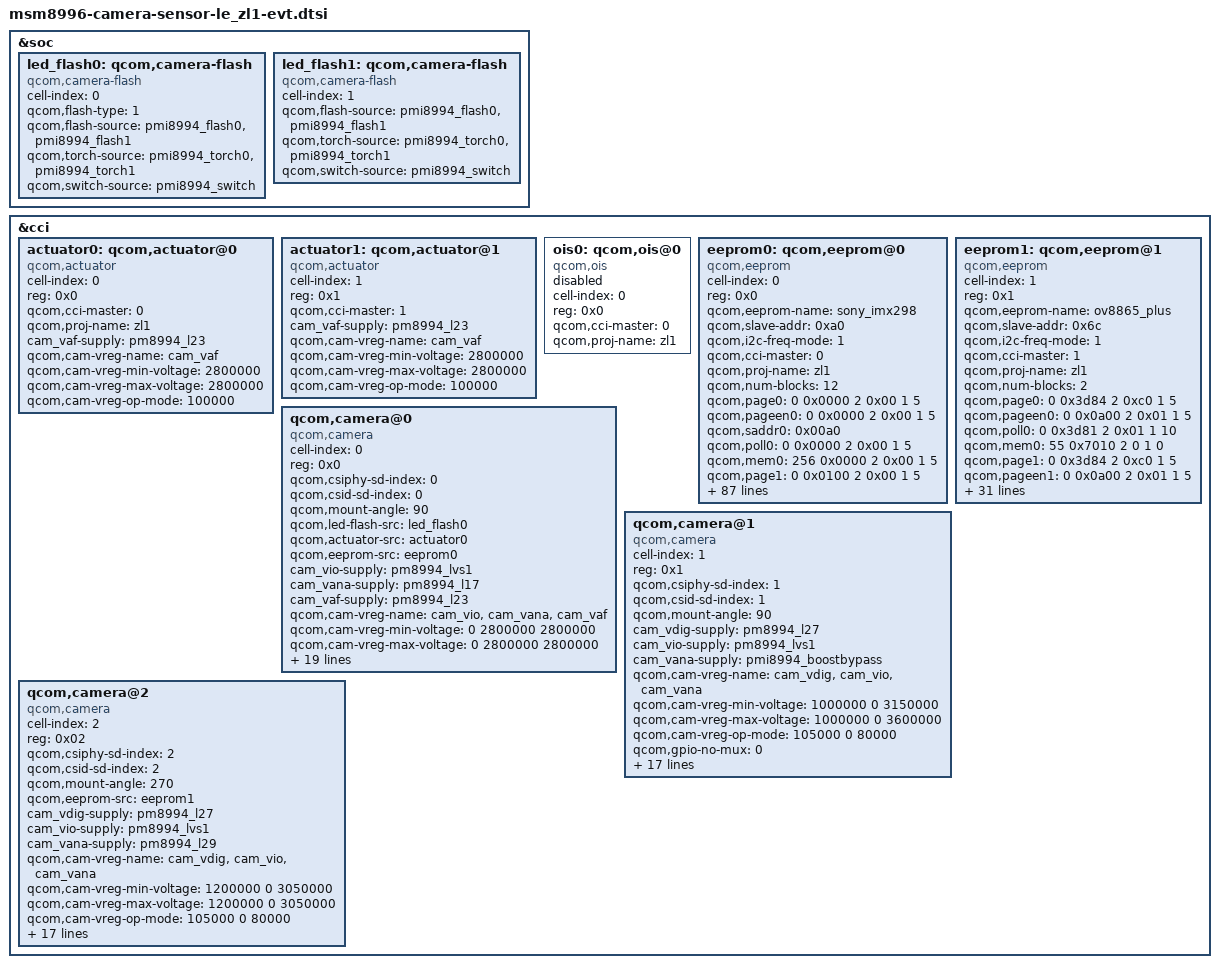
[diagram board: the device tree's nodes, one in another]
/*
 * Copyright (c) 2015 The Linux Foundation. All rights reserved.
 *
 * This program is free software; you can redistribute it and/or modify
 * it under the terms of the GNU General Public License version 2 and
 * only version 2 as published by the Free Software Foundation.
 *
 * This program is distributed in the hope that it will be useful,
 * but WITHOUT ANY WARRANTY; without even the implied warranty of
 * MERCHANTABILITY or FITNESS FOR A PARTICULAR PURPOSE.  See the
 * GNU General Public License for more details.
 */

&soc {
	led_flash0: qcom,camera-flash {
		cell-index = <0>;
		compatible = "qcom,camera-flash";
		qcom,flash-type = <1>;
		qcom,flash-source = <&pmi8994_flash0 &pmi8994_flash1>;
		qcom,torch-source = <&pmi8994_torch0 &pmi8994_torch1>;
		qcom,switch-source = <&pmi8994_switch>;
	};

	led_flash1: qcom,camera-flash {
		cell-index = <1>;
		compatible = "qcom,camera-flash";
		qcom,flash-source = <&pmi8994_flash0 &pmi8994_flash1>;
		qcom,torch-source = <&pmi8994_torch0 &pmi8994_torch1>;
		qcom,switch-source = <&pmi8994_switch>;
	};
};

&cci {
	actuator0: qcom,actuator@0 {
		cell-index = <0>;
		reg = <0x0>;
		compatible = "qcom,actuator";
		qcom,cci-master = <0>;
		qcom,proj-name = "zl1";
		cam_vaf-supply = <&pm8994_l23>;
		qcom,cam-vreg-name = "cam_vaf";
		qcom,cam-vreg-min-voltage = <2800000>;
		qcom,cam-vreg-max-voltage = <2800000>;
		qcom,cam-vreg-op-mode = <100000>;
	};

	actuator1: qcom,actuator@1 {
		cell-index = <1>;
		reg = <0x1>;
		compatible = "qcom,actuator";
		qcom,cci-master = <1>;
		cam_vaf-supply = <&pm8994_l23>;
		qcom,cam-vreg-name = "cam_vaf";
		qcom,cam-vreg-min-voltage = <2800000>;
		qcom,cam-vreg-max-voltage = <2800000>;
		qcom,cam-vreg-op-mode = <100000>;
	};

	ois0: qcom,ois@0 {
		cell-index = <0>;
		reg = <0x0>;
		compatible = "qcom,ois";
		qcom,cci-master = <0>;
		qcom,proj-name = "zl1";
		status = "disabled";
		/*
		cam_vaf-supply = <&pm8994_l23>;
		qcom,cam-vreg-name = "cam_vaf";
		qcom,cam-vreg-min-voltage = <2800000>;
		qcom,cam-vreg-max-voltage = <2800000>;
		qcom,cam-vreg-op-mode = <100000>;
		*/
	};

	eeprom0: qcom,eeprom@0 {
		cell-index = <0>;
		reg = <0x0>;
		qcom,eeprom-name = "sony_imx298";
		compatible = "qcom,eeprom";
		qcom,slave-addr = <0xa0>;
		qcom,i2c-freq-mode = <1>;
		qcom,cci-master = <0>;
		qcom,proj-name = "zl1";
		qcom,num-blocks = <12>;
		qcom,page0 = <0 0x0000 2 0x00 1 5>;
		qcom,pageen0 = <0 0x0000 2 0x00 1 5>;
		qcom,saddr0 = <0x00a0>;
		qcom,poll0 = <0 0x0000 2 0x00 1 5>;
		qcom,mem0 = <256 0x0000 2  0x00 1 5>;

		qcom,page1 = <0 0x0100 2 0x00 1 5>;
		qcom,pageen1 = <0 0x0100 2 0x00 1 5>;
		qcom,saddr1 = <0x00a0>;
		qcom,poll1 = <0 0x0100 2 0x00 1 5>;
		qcom,mem1 = <256 0x0100 2 0x00 1 0>;

		qcom,page2 = <0 0x0200 2 0x00 1 5>;
		qcom,pageen2 = <0 0x0200 2 0x00 1 5>;
		qcom,saddr2 = <0x00a0>;
		qcom,poll2 = <0 0x0200 2 0x00 1 5>;
		qcom,mem2 = <256 0x0200 2 0x00 1 0>;

		qcom,page3 = <0 0x0300 2 0x00 1 5>;
		qcom,pageen3 = <0 0x0300 2 0x00 1 5>;
		qcom,saddr3 = <0x00a0>;
		qcom,poll3 = <0 0x0300 2 0x00 1 5>;
		qcom,mem3 = <256 0x0300 2  0x00 1 5 >;

		qcom,page4 = <0 0x0400 2 0x00 1 5>;
		qcom,pageen4 = <0 0x0400 2 0x00 1 5>;
		qcom,saddr4 = <0x00a0>;
		qcom,poll4 = <0 0x0400 2 0x00 1 5>;
		qcom,mem4 = <256 0x0400 2 0x00 1 5>;

		qcom,page5 = <0 0x0500 2 0x00 1 5>;
		qcom,pageen5 = <0 0x0500 2 0x00 1 5>;
		qcom,saddr5 = <0x00a0>;
		qcom,poll5 = <0 0x0500 2 0x00 1 5>;
		qcom,mem5 = <256 0x0500 2  0x00 1 5>;

		qcom,page6 = <0 0x0600 2 0x00 1 5>;
		qcom,pageen6 = <0 0x0600 2 0x00 1 5>;
		qcom,saddr6 = <0x00a0>;
		qcom,poll6 = <0 0x0600 2 0x00 1 5>;
		qcom,mem6 = <256 0x0600 2 0x00 1 5>;

		qcom,page7 = <0 0x0700 2 0x00 1 5>;
		qcom,pageen7 = <0 0x0700 2 0x00 1 5>;
		qcom,saddr7 = <0x00a0>;
		qcom,poll7 = <0 0x0700 2 0x00 1 5>;
		qcom,mem7 = <256 0x0700 2 0x00 1 5>;

		qcom,page8 = <0 0x0800 2 0x00 1 5>;
		qcom,pageen8 = <0 0x0800 2 0x00 1 5>;
		qcom,saddr8 = <0x00a0>;
		qcom,poll8 = <0 0x0800 2 0x00 1 5>;
		qcom,mem8 = <256 0x0800 2  0x00 1 5>;

		qcom,page9 = <0 0x0900 2 0x00 1 5>;
		qcom,pageen9 = <0 0x0900 2 0x00 1 5>;
		qcom,saddr9 = <0x00a0>;
		qcom,poll9 = <0 0x0900 2 0x00 1 5>;
		qcom,mem9 = <256 0x0900 2  0x00 1 5>;

		qcom,page10 = <0 0x0A00 2 0x00 1 5>;
		qcom,pageen10 = <0 0x0A00 2 0x00 1 5>;
		qcom,saddr10 = <0x00a0>;
		qcom,poll10 = <0 0x0A00 2 0x00 1 5>;
		qcom,mem10 = <256 0x0A00 2  0x00 1 5>;

		qcom,page11 = <0 0x0B00 2 0x00 1 5>;
		qcom,pageen11 = <0 0x0B00 2 0x00 1 5>;
		qcom,saddr11 = <0x00a0>;
		qcom,poll11 = <0 0x0B00 2 0x00 1 5>;
		qcom,mem11 = <160 0x0B00 2  0x00 1 5>;

		cam_vio-supply = <&pm8994_lvs1>;
		cam_vana-supply = <&pm8994_l17>;
		cam_vaf-supply = <&pm8994_l23>;
		qcom,cam-vreg-name = "cam_vdig", "cam_vio", "cam_vana","cam_vaf";
		qcom,cam-vreg-min-voltage = <1100000 0 2500000 2800000>;
		qcom,cam-vreg-max-voltage = <1100000 0 2500000 2800000>;
		qcom,cam-vreg-op-mode = <105000 0 80000 100000>;
		qcom,gpio-no-mux = <0>;
		pinctrl-names = "cam_default", "cam_suspend";
		pinctrl-0 = <&cam_sensor_mclk0_active &cam_sensor_rear_active>;
		pinctrl-1 = <&cam_sensor_mclk0_suspend &cam_sensor_rear_suspend>;
		gpios = <&tlmm 13 0>,
			<&tlmm 29 0>,
			<&tlmm 38 0>;
		qcom,gpio-reset = <1>;
		qcom,gpio-vdig = <2>;
		qcom,gpio-req-tbl-num = <0 1 2>;
		qcom,gpio-req-tbl-flags = <1 0 0>;
		qcom,gpio-req-tbl-label = "CAMIF_MCLK0",
					  "CAM_RESET0",
					  "CAM_VDIG";
		qcom,cam-power-seq-type = "sensor_gpio", "sensor_vreg", "sensor_gpio",
			"sensor_vreg", "sensor_vreg" , "sensor_clk","sensor_gpio";
		qcom,cam-power-seq-val = "sensor_gpio_reset", "cam_vana", "sensor_gpio_vdig",
			"cam_vio", "cam_vaf","sensor_cam_mclk","sensor_gpio_reset";
		qcom,cam-power-seq-cfg-val = <1 1 1 1 1 24000000 0>;
		qcom,cam-power-seq-delay = <1 1 1 30 30 5 1>;
		status = "ok";
		clocks = <&clock_mmss clk_mclk0_clk_src>,
				<&clock_mmss clk_camss_mclk0_clk>;
		clock-names = "cam_src_clk", "cam_clk";
	};

	eeprom1: qcom,eeprom@1 {
		cell-index = <1>;
		reg = <0x1>;
		qcom,eeprom-name = "ov8865_plus";
		compatible = "qcom,eeprom";
		qcom,slave-addr = <0x6c>;
		qcom,i2c-freq-mode = <1>;
		qcom,cci-master = <1>;
		qcom,proj-name = "zl1";
		qcom,num-blocks = <2>;

		qcom,page0 = <0 0x3d84 2 0xc0 1 5>;
		qcom,pageen0 = <0 0x0a00 2 0x01 1 5>;
		qcom,poll0 = <0 0x3d81 2 0x01 1 10>;
		qcom,mem0 = <55 0x7010 2 0 1 0>;

		qcom,page1 = <0 0x3d84 2 0xc0 1 5>;
		qcom,pageen1 = <0 0x0a00 2 0x01 1 5>;
		qcom,poll1 = <0 0x3d81 2 0x01 1 10>;
		qcom,mem1 = <231 0x7047 2 0 1 0>;

		cam_vdig-supply = <&pm8994_l27>;
		cam_vio-supply = <&pm8994_lvs1>;
		cam_vana-supply = <&pm8994_l29>;
		qcom,cam-vreg-name = "cam_vdig", "cam_vio", "cam_vana";
		qcom,cam-vreg-min-voltage = <1200000 0 2800000>;
		qcom,cam-vreg-max-voltage = <1200000 0 2800000>;
		qcom,cam-vreg-op-mode = <105000 0 80000>;
		qcom,gpio-no-mux = <0>;
		pinctrl-names = "cam_default", "cam_suspend";
		pinctrl-0 = <&cam_sensor_mclk2_active &cam_sensor_front_active>;
		pinctrl-1 = <&cam_sensor_mclk2_suspend &cam_sensor_front_suspend>;
		gpios = <&tlmm 15 0>,
			<&tlmm 23 0>;
		qcom,gpio-reset = <1>;
		qcom,gpio-req-tbl-num = <0 1>;
		qcom,gpio-req-tbl-flags = <1 0>;
		qcom,gpio-req-tbl-label = "CAMIF_MCLK2",
					  "CAM_RESET2";
		qcom,cam-power-seq-type = "sensor_gpio", "sensor_vreg", "sensor_vreg",
			"sensor_vreg", "sensor_clk" , "sensor_gpio";
		qcom,cam-power-seq-val = "sensor_gpio_reset", "cam_vio", "cam_vana",
			"cam_vdig", "sensor_cam_mclk","sensor_gpio_reset";
		qcom,cam-power-seq-cfg-val = <0 1 1 1 24000000 1>;
		qcom,cam-power-seq-delay = <5 0 0 0 1 1>;
		status = "ok";
		clocks = <&clock_mmss clk_mclk2_clk_src>,
				<&clock_mmss clk_camss_mclk2_clk>;
		clock-names = "cam_src_clk", "cam_clk";
	};

	qcom,camera@0 {
		cell-index = <0>;
		compatible = "qcom,camera";
		reg = <0x0>;
		qcom,csiphy-sd-index = <0>;
		qcom,csid-sd-index = <0>;
		qcom,mount-angle = <90>;
		qcom,led-flash-src = <&led_flash0>;
		qcom,actuator-src = <&actuator0>;
		qcom,eeprom-src = <&eeprom0>;
		cam_vio-supply = <&pm8994_lvs1>;
		cam_vana-supply = <&pm8994_l17>;
		cam_vaf-supply = <&pm8994_l23>;
		qcom,cam-vreg-name = "cam_vio", "cam_vana", "cam_vaf";
		qcom,cam-vreg-min-voltage = <0 2800000 2800000>;
		qcom,cam-vreg-max-voltage = <0 2800000 2800000>;
		qcom,cam-vreg-op-mode = <0 80000 100000>;
		qcom,gpio-no-mux = <0>;
		pinctrl-names = "cam_default", "cam_suspend";
		pinctrl-0 = <&cam_sensor_mclk0_active &cam_sensor_rear_active>;
		pinctrl-1 = <&cam_sensor_mclk0_suspend &cam_sensor_rear_suspend>;
		gpios = <&tlmm 13 0>,
			<&tlmm 29 0>,
			<&tlmm 38 0>;
		qcom,gpio-reset = <1>;
		qcom,gpio-vdig = <2>;
		qcom,gpio-req-tbl-num = <0 1 2>;
		qcom,gpio-req-tbl-flags = <1 0 0>;
		qcom,gpio-req-tbl-label = "CAMIF_MCLK0",
					  "CAM_RESET0",
					  "CAM_VDIG";
		qcom,sensor-position = <0>;
		qcom,sensor-mode = <0>;
		qcom,cci-master = <0>;
		qcom,proj-name = "zl1";
		status = "ok";
		clocks = <&clock_mmss clk_mclk0_clk_src>,
				<&clock_mmss clk_camss_mclk0_clk>;
		clock-names = "cam_src_clk", "cam_clk";
	};

	qcom,camera@1 {
		cell-index = <1>;
		compatible = "qcom,camera";
		reg = <0x1>;
		qcom,csiphy-sd-index = <1>;
		qcom,csid-sd-index = <1>;
		qcom,mount-angle = <90>;
		cam_vdig-supply = <&pm8994_l27>;
		cam_vio-supply = <&pm8994_lvs1>;
		cam_vana-supply = <&pmi8994_boostbypass>;
		qcom,cam-vreg-name = "cam_vdig", "cam_vio", "cam_vana";
		qcom,cam-vreg-min-voltage = <1000000 0 3150000>;
		qcom,cam-vreg-max-voltage = <1000000 0 3600000>;
		qcom,cam-vreg-op-mode = <105000 0 80000>;
		qcom,gpio-no-mux = <0>;
		pinctrl-names = "cam_default", "cam_suspend";
		pinctrl-0 = <&cam_sensor_mclk1_active &cam_sensor_rear2_active>;
		pinctrl-1 = <&cam_sensor_mclk1_suspend &cam_sensor_rear2_suspend>;
		gpios = <&tlmm 14 0>,
			<&tlmm 63 0>,
			<&tlmm 62 0>;
		qcom,gpio-reset = <1>;
		qcom,gpio-standby = <2>;
		qcom,gpio-req-tbl-num = <0 1 2>;
		qcom,gpio-req-tbl-flags = <1 0 0>;
		qcom,gpio-req-tbl-label = "CAMIF_MCLK1",
					  "CAM_RESET1",
					  "CAM_STANDBY1";
		qcom,sensor-position = <0>;
		qcom,sensor-mode = <0>;
		qcom,cci-master = <0>;
		qcom,proj-name = "zl1";
		status = "ok";
		clocks = <&clock_mmss clk_mclk1_clk_src>,
			<&clock_mmss clk_camss_mclk1_clk>;
		clock-names = "cam_src_clk", "cam_clk";
	};

	qcom,camera@2 {
		cell-index = <2>;
		compatible = "qcom,camera";
		reg = <0x02>;
		qcom,csiphy-sd-index = <2>;
		qcom,csid-sd-index = <2>;
		qcom,mount-angle = <270>;
		qcom,eeprom-src = <&eeprom1>;
		cam_vdig-supply = <&pm8994_l27>;
		cam_vio-supply = <&pm8994_lvs1>;
		cam_vana-supply = <&pm8994_l29>;
		qcom,cam-vreg-name = "cam_vdig", "cam_vio", "cam_vana";
		qcom,cam-vreg-min-voltage = <1200000 0 3050000>;
		qcom,cam-vreg-max-voltage = <1200000 0 3050000>;
		qcom,cam-vreg-op-mode = <105000 0 80000>;
		qcom,gpio-no-mux = <0>;
		pinctrl-names = "cam_default", "cam_suspend";
		pinctrl-0 = <&cam_sensor_mclk2_active &cam_sensor_front_active>;
		pinctrl-1 = <&cam_sensor_mclk2_suspend &cam_sensor_front_suspend>;
		gpios = <&tlmm 15 0>,
			<&tlmm 23 0>;
		qcom,gpio-reset = <1>;
		qcom,gpio-req-tbl-num = <0 1>;
		qcom,gpio-req-tbl-flags = <1 0>;
		qcom,gpio-req-tbl-label = "CAMIF_MCLK2",
					  "CAM_RESET2";
		qcom,sensor-position = <1>;
		qcom,sensor-mode = <0>;
		qcom,cci-master = <1>;
		qcom,proj-name = "zl1";
		status = "ok";
		clocks = <&clock_mmss clk_mclk2_clk_src>,
			<&clock_mmss clk_camss_mclk2_clk>;
		clock-names = "cam_src_clk", "cam_clk";
	};
};
